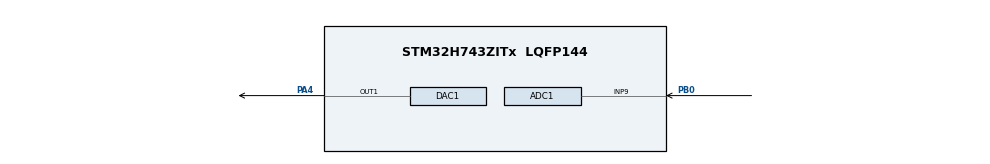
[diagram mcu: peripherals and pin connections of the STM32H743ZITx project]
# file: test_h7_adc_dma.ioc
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ADC1.Channel-2\#ChannelRegularConversion=ADC_CHANNEL_9
ADC1.ConversionDataManagement=ADC_CONVERSIONDATA_DMA_CIRCULAR
ADC1.ExternalTrigConv=ADC_EXTERNALTRIG_T4_TRGO
ADC1.LeftBitShift=ADC_LEFTBITSHIFT_NONE
ADC1.NbrOfConversionFlag=1
ADC1.OffsetNumber-2\#ChannelRegularConversion=ADC_OFFSET_NONE
ADC1.OffsetSignedSaturation-2\#ChannelRegularConversion=DISABLE
ADC1.Overrun=ADC_OVR_DATA_OVERWRITTEN
ADC1.Rank-2\#ChannelRegularConversion=1
ADC1.SamplingTime-2\#ChannelRegularConversion=ADC_SAMPLETIME_16CYCLES_5
ADC1.master=1
DAC1.DAC_Channel-DAC_OUT1=DAC_CHANNEL_1
Dma.ADC1.0.Direction=DMA_PERIPH_TO_MEMORY
Dma.ADC1.0.EventEnable=DISABLE
Dma.ADC1.0.FIFOMode=DMA_FIFOMODE_DISABLE
Dma.ADC1.0.Instance=DMA1_Stream0
Dma.ADC1.0.MemDataAlignment=DMA_MDATAALIGN_HALFWORD
Dma.ADC1.0.MemInc=DMA_MINC_ENABLE
Dma.ADC1.0.Mode=DMA_CIRCULAR
Dma.ADC1.0.PeriphDataAlignment=DMA_PDATAALIGN_HALFWORD
Dma.ADC1.0.PeriphInc=DMA_PINC_DISABLE
Dma.ADC1.0.Polarity=HAL_DMAMUX_REQ_GEN_RISING
Dma.ADC1.0.Priority=DMA_PRIORITY_LOW
Dma.ADC1.0.RequestNumber=1
Dma.ADC1.0.SignalID=NONE
Dma.ADC1.0.SyncEnable=DISABLE
Dma.ADC1.0.SyncPolarity=HAL_DMAMUX_SYNC_NO_EVENT
Dma.ADC1.0.SyncRequestNumber=1
Dma.ADC1.0.SyncSignalID=NONE
Dma.Request0=ADC1
Mcu.Family=STM32H7
Mcu.Name=STM32H743ZITx
Mcu.Package=LQFP144
NVIC.DMA1_Stream0_IRQn=true\:0\:0\:false\:false\:true\:false\:true\:true
NVIC.PriorityGroup=NVIC_PRIORITYGROUP_4
PA4.Signal=COMP_DAC11_group
PB0.Signal=ADCx_INP9
PH0-OSC_IN\ (PH0).Mode=HSE-External-Oscillator
PH0-OSC_IN\ (PH0).Signal=RCC_OSC_IN
PH1-OSC_OUT\ (PH1).Mode=HSE-External-Oscillator
PH1-OSC_OUT\ (PH1).Signal=RCC_OSC_OUT
ProjectManager.HeapSize=0x200
ProjectManager.StackSize=0x400
ProjectManager.TargetToolchain=MDK-ARM V5.32
RCC.ADCFreq_Value=40000000
RCC.APB1Freq_Value=100000000
RCC.APB2Freq_Value=100000000
RCC.APB3Freq_Value=100000000
RCC.APB4Freq_Value=100000000
RCC.CortexFreq_Value=200000000
RCC.DIVM1=2
RCC.DIVM2=4
RCC.DIVN1=200
RCC.DIVN2=80
RCC.DIVP1=4
RCC.DIVP2=4
RCC.HCLKFreq_Value=100000000
RCC.HPRE=RCC_HCLK_DIV2
RCC.HSE_VALUE=8000000
RCC.PLLSourceVirtual=RCC_PLLSOURCE_HSE
RCC.SYSCLKFreq_VALUE=200000000
RCC.SYSCLKSource=RCC_SYSCLKSOURCE_PLLCLK
RCC.USBFreq_Value=400000000
SH.ADCx_INP9.0=ADC1_INP9,IN9-Single-Ended
SH.COMP_DAC11_group.0=DAC1_OUT1,DAC_OUT1
TIM4.AutoReloadPreload=TIM_AUTORELOAD_PRELOAD_ENABLE
TIM4.Period=100
TIM4.Prescaler=99
TIM4.TIM_MasterOutputTrigger=TIM_TRGO_UPDATE
TIM4.TIM_MasterSlaveMode=TIM_MASTERSLAVEMODE_DISABLE
VP_TIM4_VS_ClockSourceINT.Mode=Internal
board=custom

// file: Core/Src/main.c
/* USER CODE BEGIN Header */
/**
  ******************************************************************************
  * @file           : main.c
  * @brief          : Проект тестового задания для НТО ИРЭ-Полюс.
	* @author Ананин Николай
	* @date 03.04.2023
  ******************************************************************************
  * @attention
  *	Задание:
	*
	* Необходимо реализовать чтение значений со входа АЦП с использованием DMA с дискретизацией 10 КГц и
	* установки полученных усреднённых значений на выходе ЦАП раз в милисекунду.  А также выдаче усреднённых за
	* 1 секунду значений по SWD интерфейсу в терминал IDE Keil. Полученные значения выводить в мили вольтах,
	* формат представления в ASCII кодах с символом перевода строки на конце (пример: «1500 mV\r\n»).
	* Выбор ножек на ваше усмотрение.
	* Проект необходимо сгенерировать в STM32CubeMX для среды Keil с использованием библиотек «LL» для АЦП,
	* для остальной периферии на «HAL».
	* Описание полученного кода сформировать в формате Doxygen.
	* По факту выполнения выложить в доступный GIT репозиторий.
  *
  * Описание решения:
  *
  * Для решения поставленной задачи выбрана макетная плата NUCLEO-H743ZI2 (микроконтроллер STM32H743ZI).
	* Используется следующая перифирия TIM4, ADC1, DMA, DAC. Тактовая частота ядра была настроена на 200МГц,
	* тактовая частота шин TIM4, ADC1 100 МГц. Измерение ADC1 запускается по триггеру с таймера, который
	* устанавливается с частотой 10 кГц. Измерения ADC записываются в буфер через DMA. Буфер имеет двойной
	* размер, чтобы не останавливать измерение ADC пока выполняется обработка ранее принятых данных. Прерывание DMA срабатывает
	* при заполнении половины буфера и полного буфера. DMA настроен на циклический режим, чтобы измерение
	* производилось без остановки. Вычисление среднего значения напряжения и вывод в терминал реализовано
	* в основном потоке, чтобы разгрузить обработку прерывания.
	*
	* Получившийся проект добавил в систему контроля версий GIT (исключил папку с obj файлами и файлы настройки отладчика) и выложил в публичный репозиторий GitHub:
	* https://github.com/ns-ananin/test_h7_adc_dma.git
	*
	* Проект STM32CubeMX находится в репозитории.
  *
  ******************************************************************************
  */
/* USER CODE END Header */
#include "main.h"

/* USER CODE BEGIN Includes */
#include "EventRecorder.h"
#include "PeripheralAPI.h"
#include "TestTask.h"
/* USER CODE END Includes */

DAC_HandleTypeDef hdac1;

TIM_HandleTypeDef htim4;

/* USER CODE BEGIN PV */
/// Размер буфера для сохранения данных с АЦП.
#define sizeBuffer 10

/// Буфер для сохранения данных с АЦП. Двойной размер буфера выбран, чтобы в одну часть
/// писать данные с АЦП, а другую часть обрабатывать.
static uint16_t buffer[sizeBuffer * 2]__attribute__((section(".ARM.__at_0x24000000")));

/* USER CODE END PV */

void SystemClock_Config(void);
static void MX_GPIO_Init(void);
static void MX_DMA_Init(void);
static void MX_ADC1_Init(void);
static void MX_TIM4_Init(void);
static void MX_DAC1_Init(void);

/* USER CODE BEGIN 0 */

/**
* \brief Обработать прерывание DMA.
 * @param isFullBuffer true - заполнена вторая половина буфера, false - заполнена первая половина буфера.
 */
void handleDMAinterrupt(char isFullBuffer){
	TestTask_processADCvalues(isFullBuffer ? &buffer[sizeBuffer] : buffer, sizeBuffer);
}

void PeripheralAPI_setValueInDAC(uint32_t newValue){
	HAL_DAC_SetValue(&hdac1, DAC_CHANNEL_1, DAC_ALIGN_12B_R, newValue);
}

/* USER CODE END 0 */

int main(void)
{
  /* USER CODE BEGIN 1 */
	EventRecorderInitialize( EventRecordAll, 1 );
  /* USER CODE END 1 */

  /* MCU Configuration--------------------------------------------------------*/

  /* Reset of all peripherals, Initializes the Flash interface and the Systick. */
  HAL_Init();

  /* Configure the system clock */
  SystemClock_Config();

  /* Initialize all configured peripherals */
  MX_GPIO_Init();
  MX_DMA_Init();
  MX_ADC1_Init();
  MX_TIM4_Init();
  MX_DAC1_Init();
  /* USER CODE BEGIN 2 */
	LL_DMA_SetPeriphAddress(DMA1, LL_DMA_STREAM_0,(uint32_t)&ADC1->DR);// Настраиваем у DMA адрес исочника данных.
	LL_DMA_SetMemoryAddress(DMA1, LL_DMA_STREAM_0, (uint32_t)buffer);// Указываем DMA на приемник данных.
	LL_DMA_SetDataLength(DMA1, LL_DMA_STREAM_0, sizeBuffer * 2); // Указываем DMA размер приемника.
	LL_DMA_EnableIT_HT(DMA1, LL_DMA_STREAM_0); // Включаем прерывание по заполнению половины буфера.
	LL_DMA_EnableIT_TC(DMA1, LL_DMA_STREAM_0); // Включаем прерывание по заполнению всего буфера.
	LL_DMA_EnableStream(DMA1, LL_DMA_STREAM_0); // Запускаем DMA.
	LL_ADC_Enable(ADC1);												// Запускаем ADC.

	while(LL_ADC_IsActiveFlag_ADRDY(ADC1) != SET);
	LL_ADC_REG_StartConversion(ADC1);// Запускаем измерение.

	HAL_TIM_Base_Start(&htim4);// Запускаем таймер.
  /* USER CODE END 2 */

  /* Infinite loop */
  /* USER CODE BEGIN WHILE */
  while (1)
  {
		TestTask_execute();
    /* USER CODE END WHILE */

  }
}

void SystemClock_Config(void)
{
  RCC_OscInitTypeDef RCC_OscInitStruct = {0};
  RCC_ClkInitTypeDef RCC_ClkInitStruct = {0};

  /** Supply configuration update enable
  */
  HAL_PWREx_ConfigSupply(PWR_LDO_SUPPLY);

  /** Configure the main internal regulator output voltage
  */
  __HAL_PWR_VOLTAGESCALING_CONFIG(PWR_REGULATOR_VOLTAGE_SCALE3);

  while(!__HAL_PWR_GET_FLAG(PWR_FLAG_VOSRDY)) {}

  /** Initializes the RCC Oscillators according to the specified parameters
  * in the RCC_OscInitTypeDef structure.
  */
  RCC_OscInitStruct.OscillatorType = RCC_OSCILLATORTYPE_HSE;
  RCC_OscInitStruct.HSEState = RCC_HSE_ON;
  RCC_OscInitStruct.PLL.PLLState = RCC_PLL_ON;
  RCC_OscInitStruct.PLL.PLLSource = RCC_PLLSOURCE_HSE;
  RCC_OscInitStruct.PLL.PLLM = 2;
  RCC_OscInitStruct.PLL.PLLN = 200;
  RCC_OscInitStruct.PLL.PLLP = 4;
  RCC_OscInitStruct.PLL.PLLQ = 2;
  RCC_OscInitStruct.PLL.PLLR = 2;
  RCC_OscInitStruct.PLL.PLLRGE = RCC_PLL1VCIRANGE_2;
  RCC_OscInitStruct.PLL.PLLVCOSEL = RCC_PLL1VCOWIDE;
  RCC_OscInitStruct.PLL.PLLFRACN = 0;
  if (HAL_RCC_OscConfig(&RCC_OscInitStruct) != HAL_OK)
  {
    Error_Handler();
  }

  /** Initializes the CPU, AHB and APB buses clocks
  */
  RCC_ClkInitStruct.ClockType = RCC_CLOCKTYPE_HCLK|RCC_CLOCKTYPE_SYSCLK
                              |RCC_CLOCKTYPE_PCLK1|RCC_CLOCKTYPE_PCLK2
                              |RCC_CLOCKTYPE_D3PCLK1|RCC_CLOCKTYPE_D1PCLK1;
  RCC_ClkInitStruct.SYSCLKSource = RCC_SYSCLKSOURCE_PLLCLK;
  RCC_ClkInitStruct.SYSCLKDivider = RCC_SYSCLK_DIV1;
  RCC_ClkInitStruct.AHBCLKDivider = RCC_HCLK_DIV2;
  RCC_ClkInitStruct.APB3CLKDivider = RCC_APB3_DIV1;
  RCC_ClkInitStruct.APB1CLKDivider = RCC_APB1_DIV1;
  RCC_ClkInitStruct.APB2CLKDivider = RCC_APB2_DIV1;
  RCC_ClkInitStruct.APB4CLKDivider = RCC_APB4_DIV1;

  if (HAL_RCC_ClockConfig(&RCC_ClkInitStruct, FLASH_LATENCY_2) != HAL_OK)
  {
    Error_Handler();
  }
}

static void MX_ADC1_Init(void)
{

  LL_ADC_InitTypeDef ADC_InitStruct = {0};
  LL_ADC_REG_InitTypeDef ADC_REG_InitStruct = {0};
  LL_ADC_CommonInitTypeDef ADC_CommonInitStruct = {0};

  LL_GPIO_InitTypeDef GPIO_InitStruct = {0};
  RCC_PeriphCLKInitTypeDef PeriphClkInitStruct = {0};

  /** Initializes the peripherals clock
  */
  PeriphClkInitStruct.PeriphClockSelection = RCC_PERIPHCLK_ADC;
  PeriphClkInitStruct.PLL2.PLL2M = 4;
  PeriphClkInitStruct.PLL2.PLL2N = 80;
  PeriphClkInitStruct.PLL2.PLL2P = 4;
  PeriphClkInitStruct.PLL2.PLL2Q = 2;
  PeriphClkInitStruct.PLL2.PLL2R = 2;
  PeriphClkInitStruct.PLL2.PLL2RGE = RCC_PLL2VCIRANGE_1;
  PeriphClkInitStruct.PLL2.PLL2VCOSEL = RCC_PLL2VCOMEDIUM;
  PeriphClkInitStruct.PLL2.PLL2FRACN = 0;
  PeriphClkInitStruct.AdcClockSelection = RCC_ADCCLKSOURCE_PLL2;
  if (HAL_RCCEx_PeriphCLKConfig(&PeriphClkInitStruct) != HAL_OK)
  {
    Error_Handler();
  }

  /* Peripheral clock enable */
  LL_AHB1_GRP1_EnableClock(LL_AHB1_GRP1_PERIPH_ADC12);

  LL_AHB4_GRP1_EnableClock(LL_AHB4_GRP1_PERIPH_GPIOB);
  /**ADC1 GPIO Configuration
  PB0   ------> ADC1_INP9
  */
  GPIO_InitStruct.Pin = LL_GPIO_PIN_0;
  GPIO_InitStruct.Mode = LL_GPIO_MODE_ANALOG;
  GPIO_InitStruct.Pull = LL_GPIO_PULL_NO;
  LL_GPIO_Init(GPIOB, &GPIO_InitStruct);

  /* ADC1 DMA Init */

  /* ADC1 Init */
  LL_DMA_SetPeriphRequest(DMA1, LL_DMA_STREAM_0, LL_DMAMUX1_REQ_ADC1);

  LL_DMA_SetDataTransferDirection(DMA1, LL_DMA_STREAM_0, LL_DMA_DIRECTION_PERIPH_TO_MEMORY);

  LL_DMA_SetStreamPriorityLevel(DMA1, LL_DMA_STREAM_0, LL_DMA_PRIORITY_LOW);

  LL_DMA_SetMode(DMA1, LL_DMA_STREAM_0, LL_DMA_MODE_CIRCULAR);

  LL_DMA_SetPeriphIncMode(DMA1, LL_DMA_STREAM_0, LL_DMA_PERIPH_NOINCREMENT);

  LL_DMA_SetMemoryIncMode(DMA1, LL_DMA_STREAM_0, LL_DMA_MEMORY_INCREMENT);

  LL_DMA_SetPeriphSize(DMA1, LL_DMA_STREAM_0, LL_DMA_PDATAALIGN_HALFWORD);

  LL_DMA_SetMemorySize(DMA1, LL_DMA_STREAM_0, LL_DMA_MDATAALIGN_HALFWORD);

  LL_DMA_DisableFifoMode(DMA1, LL_DMA_STREAM_0);

  /* USER CODE BEGIN ADC1_Init 1 */
	ADC_REG_InitStruct.DataTransferMode = LL_ADC_REG_DMA_TRANSFER_UNLIMITED;
	ADC_InitStruct.LeftBitShift = LL_ADC_LEFT_BIT_SHIFT_NONE;
  /* USER CODE END ADC1_Init 1 */

  /** Common config
  */
  LL_ADC_SetOverSamplingScope(ADC1, LL_ADC_OVS_DISABLE);
  ADC_InitStruct.Resolution = LL_ADC_RESOLUTION_16B;
  ADC_InitStruct.LowPowerMode = LL_ADC_LP_MODE_NONE;
  LL_ADC_Init(ADC1, &ADC_InitStruct);
  ADC_REG_InitStruct.TriggerSource = LL_ADC_REG_TRIG_EXT_TIM4_TRGO;
  ADC_REG_InitStruct.SequencerLength = LL_ADC_REG_SEQ_SCAN_DISABLE;
  ADC_REG_InitStruct.SequencerDiscont = DISABLE;
  ADC_REG_InitStruct.ContinuousMode = LL_ADC_REG_CONV_SINGLE;
  ADC_REG_InitStruct.Overrun = LL_ADC_REG_OVR_DATA_OVERWRITTEN;
  LL_ADC_REG_Init(ADC1, &ADC_REG_InitStruct);
  ADC_CommonInitStruct.CommonClock = LL_ADC_CLOCK_ASYNC_DIV1;
  ADC_CommonInitStruct.Multimode = LL_ADC_MULTI_INDEPENDENT;
  LL_ADC_CommonInit(__LL_ADC_COMMON_INSTANCE(ADC1), &ADC_CommonInitStruct);
  LL_ADC_REG_SetTriggerEdge(ADC1, LL_ADC_REG_TRIG_EXT_RISING);

  /* Disable ADC deep power down (enabled by default after reset state) */
  LL_ADC_DisableDeepPowerDown(ADC1);
  /* Enable ADC internal voltage regulator */
  LL_ADC_EnableInternalRegulator(ADC1);
  /* Delay for ADC internal voltage regulator stabilization. */
  /* Compute number of CPU cycles to wait for, from delay in us. */
  /* Note: Variable divided by 2 to compensate partially */
  /* CPU processing cycles (depends on compilation optimization). */
  /* Note: If system core clock frequency is below 200kHz, wait time */
  /* is only a few CPU processing cycles. */
  __IO uint32_t wait_loop_index;
  wait_loop_index = ((LL_ADC_DELAY_INTERNAL_REGUL_STAB_US * (SystemCoreClock / (100000 * 2))) / 10);
  while(wait_loop_index != 0)
  {
    wait_loop_index--;
  }

  /** Configure Regular Channel
  */
  LL_ADC_REG_SetSequencerRanks(ADC1, LL_ADC_REG_RANK_1, LL_ADC_CHANNEL_9);
  LL_ADC_SetChannelSamplingTime(ADC1, LL_ADC_CHANNEL_9, LL_ADC_SAMPLINGTIME_16CYCLES_5);
  LL_ADC_SetChannelSingleDiff(ADC1, LL_ADC_CHANNEL_9, LL_ADC_SINGLE_ENDED);

}

static void MX_DAC1_Init(void)
{

  DAC_ChannelConfTypeDef sConfig = {0};

  /** DAC Initialization
  */
  hdac1.Instance = DAC1;
  if (HAL_DAC_Init(&hdac1) != HAL_OK)
  {
    Error_Handler();
  }

  /** DAC channel OUT1 config
  */
  sConfig.DAC_SampleAndHold = DAC_SAMPLEANDHOLD_DISABLE;
  sConfig.DAC_Trigger = DAC_TRIGGER_NONE;
  sConfig.DAC_OutputBuffer = DAC_OUTPUTBUFFER_ENABLE;
  sConfig.DAC_ConnectOnChipPeripheral = DAC_CHIPCONNECT_DISABLE;
  sConfig.DAC_UserTrimming = DAC_TRIMMING_FACTORY;
  if (HAL_DAC_ConfigChannel(&hdac1, &sConfig, DAC_CHANNEL_1) != HAL_OK)
  {
    Error_Handler();
  }
  /* USER CODE BEGIN DAC1_Init 2 */
	HAL_DAC_Start(&hdac1, DAC_CHANNEL_1);
  /* USER CODE END DAC1_Init 2 */

}

static void MX_TIM4_Init(void)
{

  TIM_ClockConfigTypeDef sClockSourceConfig = {0};
  TIM_MasterConfigTypeDef sMasterConfig = {0};

  htim4.Instance = TIM4;
  htim4.Init.Prescaler = 99;
  htim4.Init.CounterMode = TIM_COUNTERMODE_UP;
  htim4.Init.Period = 100;
  htim4.Init.ClockDivision = TIM_CLOCKDIVISION_DIV1;
  htim4.Init.AutoReloadPreload = TIM_AUTORELOAD_PRELOAD_ENABLE;
  if (HAL_TIM_Base_Init(&htim4) != HAL_OK)
  {
    Error_Handler();
  }
  sClockSourceConfig.ClockSource = TIM_CLOCKSOURCE_INTERNAL;
  if (HAL_TIM_ConfigClockSource(&htim4, &sClockSourceConfig) != HAL_OK)
  {
    Error_Handler();
  }
  sMasterConfig.MasterOutputTrigger = TIM_TRGO_UPDATE;
  sMasterConfig.MasterSlaveMode = TIM_MASTERSLAVEMODE_DISABLE;
  if (HAL_TIMEx_MasterConfigSynchronization(&htim4, &sMasterConfig) != HAL_OK)
  {
    Error_Handler();
  }

}

static void MX_DMA_Init(void)
{

  /* Init with LL driver */
  /* DMA controller clock enable */
  LL_AHB1_GRP1_EnableClock(LL_AHB1_GRP1_PERIPH_DMA1);

  /* DMA interrupt init */
  /* DMA1_Stream0_IRQn interrupt configuration */
  NVIC_SetPriority(DMA1_Stream0_IRQn, NVIC_EncodePriority(NVIC_GetPriorityGrouping(),0, 0));
  NVIC_EnableIRQ(DMA1_Stream0_IRQn);

}

static void MX_GPIO_Init(void)
{

  /* GPIO Ports Clock Enable */
  __HAL_RCC_GPIOH_CLK_ENABLE();
  __HAL_RCC_GPIOA_CLK_ENABLE();
  __HAL_RCC_GPIOB_CLK_ENABLE();

}

void Error_Handler(void)
{
  __disable_irq();
  while (1)
  {
  }
}
